# TC35680 register map
Vendor: Toshiba Electronic Devices and Storage Corporation; File version: 0.1
CPU: CM0 r0p0, little endian, no MPU, no FPU, 4 interrupt priority bits
Registers are 32-bit, read-write, no defined reset value unless marked. A register's access mark holds for its fields unless they carry their own. Offsets are from the block's base; [hi:lo] are bit positions; {n}, {i} and the like mark numbered series.

## PMU — Power Management Unit
Base 0x40055000
0x5C PMU_RTCWAKEUPCFG — RTC wakeup config register
  [0] RTCWAKEUPEN — RTC wakeup config. 1: Enable wakeup by RTC. 0: Disable wakeup by RTC
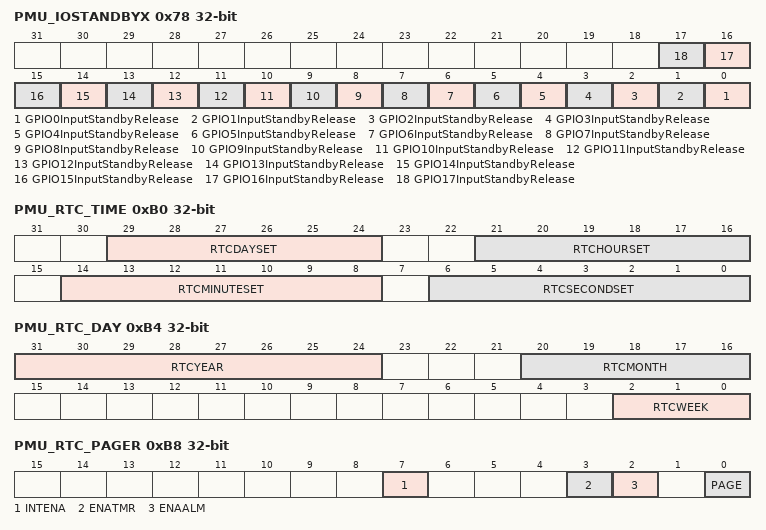
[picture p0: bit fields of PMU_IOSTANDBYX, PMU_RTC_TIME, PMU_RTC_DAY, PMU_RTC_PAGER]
0x78 PMU_IOSTANDBYX — GPIO input standby
  [n] GPIO{n}InputStandbyRelease (n=0..17) — Input standby release on GPIO{n}. 1: Release standby. 0: Standby
0xB0 PMU_RTC_TIME — RTC time register
  [29:24] RTCDAYSET — RTC time config of day. (Binary Coded Decimal). Min=1. Max=31
  [21:16] RTCHOURSET — RTC time config of hour. (Binary Coded Decimal). Min: 0. Max: 23
  [14:8] RTCMINUTESET — RTC time config of minute. (Binary Coded Decimal). Min: 0. Max: 59
  [6:0] RTCSECONDSET — RTC time config of second. (Binary Coded Decimal). Min: 0. Max: 59
0xB4 PMU_RTC_DAY — RTC date register
  [31:24] RTCYEAR — RTC date config of year. (Binary Coded Decimal)
  [20:16] RTCMONTH — RTC date config of month. (Binary Coded Decimal)
  [2:0] RTCWEEK — RTC date config of week. (Binary Coded Decimal)
0xB8 PMU_RTC_PAGER — RTC control config register
  [7] INTENA — Set interrupt config. 0: Disable. 1: Enable
  [3] ENATMR — Set clock config. 0: Disable. 1: Enable
  [2] ENAALM — Set alarm config. 0: Disable. 1: Enable
  [0] PAGE — Set Page config. 0: Choose Page0. 1: Choose Page1
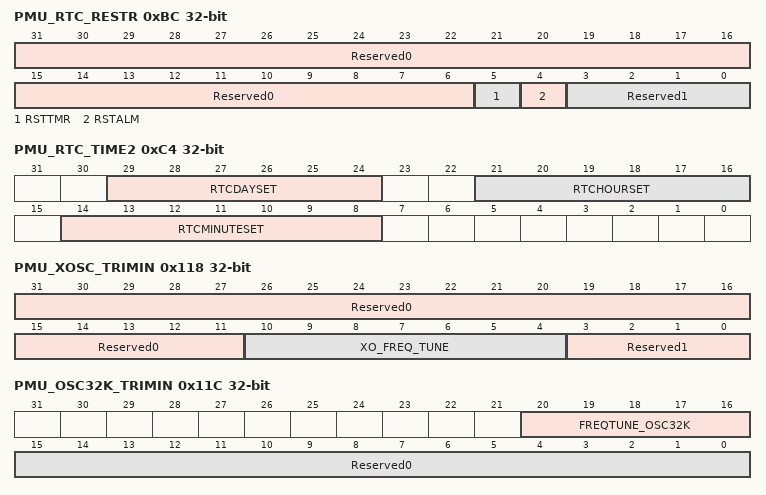
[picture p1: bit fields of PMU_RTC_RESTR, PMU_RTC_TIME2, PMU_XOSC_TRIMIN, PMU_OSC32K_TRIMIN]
0xBC PMU_RTC_RESTR — RTC reset register
  [31:6] Reserved0 — Always set 0b0000_0000_1100_0001_0000_0000_11
  [5] RSTTMR — Reset clock. 0: Not reset. 1: Reset. If you wan to reset a clock, please set 1 to this value and wait to become 0.
  [4] RSTALM — Reset alarm. 0: Not reset. 1: Reset. If you wan to reset an alarm, please set 1 to this value and wait to become 0.
  [3:0] Reserved1 — Do not change the values.
0xC4 PMU_RTC_TIME2 — RTC time register2
  [29:24] RTCDAYSET — RTC time config of day. (Binary Coded Decimal). Min: 1. Max: 31
  [21:16] RTCHOURSET — RTC time config of hour. (Binary Coded Decimal). Min: 0. Max: 23
  [14:8] RTCMINUTESET — RTC time config of minute. (Binary Coded Decimal). Min: 0. Max: 59
0xCC PMU_RTC_ADJUST1S — RTC Adjust 1 Sec register
  [8] SCUT — 1Hz Short Cut
0xD0 PMU_RTC_INTCLR — RTC interrupt clear register
  [0] RTCINTclr — Clear RTC interrupt. 1: Clear. 0: Don't care
0xD4 PMU_RTC_INTEN — RTC interrupt enable register
  [0] RTCINTEN — Enable RTC interrupt. 1: Enable interrupt request. 0: Disable interrupt request
0xD8 PMU_RTC_CNTCFG — RTC count cnofig register
  [0] RTCNTCFG — Set RTC config. 1: Enable RTC config. 0: Disable RTC config
0x118 PMU_XOSC_TRIMIN — XOSC trimming register
  [31:11] Reserved0 — Do not change this value
  [10:4] XO_FREQ_TUNE — Frequency tune value (eFuse)
  [3:0] Reserved1 — Do not change this value
0x11C PMU_OSC32K_TRIMIN — OSC32K trimming register
  [20:16] FREQTUNE_OSC32K — Freqency tune value. (eFuse)
  [15:0] Reserved0 — Do not change this value
0x160 PMU_SLEEPCLK_STATUS — Sleep clock status
  [0] SLPSLKTOGLE — Status toggling 1/2 of Sleep clock
0x164 PMU_SLEEPCLK_HL_STATUS — HL Status of Sleep Clock
  [0] SLPSLKHLSTATUS — Sleep Clock Status

## BluetoothCounter
Base 0x40040240
0x0C LLC_LLCNT_HOLD_EN — Hold Bluetooth counter
  [0] LLCntHold — When 0 (or arbitrary value) is set this register, the following registers will hold the values: LLC_BC_LATCH_MA:Master Bit Counter. LLC_SC_LATCH_MA:Master Slot Counter. Before accessing LLC_BC_LATCH_MA or LLC_SC_LATCH_MA, please set 0 (or arbitrary value) to this register.
0x20 LLC_BC_LATCH_MA ro — Holding Master Bit Counter
  [9:0] BCntMa_Hold — Master bit counter value.
0x24 LLC_SC_LATCH_MA — Holding Master Slot Counter
  [26:0] SCntMa_Hold — Master slot counter value. This counts up every 1 slot (625 micro seconds). Before reading this value, please set 0 (or arbitrary value) to LLCntHold.
